# STM32F0x0 register map
File version: 1.2
CPU: CM0 r0p0, little endian, no MPU, no FPU, 3 interrupt priority bits
Registers are 32-bit, read-write, reset 0x0 unless marked. A register's access mark holds for its fields unless they carry their own. Offsets are from the block's base; [hi:lo] are bit positions; {n}, {i} and the like mark numbered series; 'fields as' and 'values as' point back to an identical list.

## IWDG — Independent watchdog
Base 0x40003000
0x00 KR wo — Key register
  [15:0] KEY — Key value
0x04 PR — Prescaler register
  [2:0] PR — Prescaler divider
0x08 RLR reset 0xFFF — Reload register
  [11:0] RL — Watchdog counter reload value
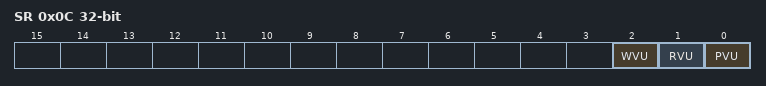
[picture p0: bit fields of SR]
0x0C SR ro — Status register
  [2] WVU — Watchdog counter window value update
  [1] RVU — Watchdog counter reload value update
  [0] PVU — Watchdog prescaler value update
0x10 WINR reset 0xFFF — Window register
  [11:0] WIN — Watchdog counter window value

## WWDG — Window watchdog
Base 0x40002C00
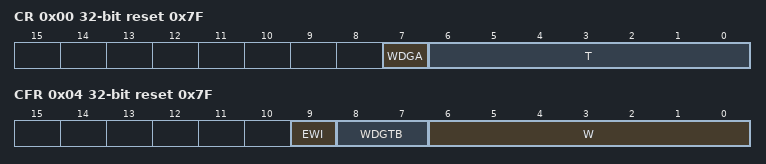
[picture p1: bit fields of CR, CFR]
0x00 CR reset 0x7F — Control register
  [7] WDGA — Activation bit
  [6:0] T — 7-bit counter
0x04 CFR reset 0x7F — Configuration register
  [9] EWI — Early wakeup interrupt
  [8:7] WDGTB — Timer base
  [6:0] W — 7-bit window value
0x08 SR — Status register
  [0] EWIF — Early wakeup interrupt flag

## EXTI — External interrupt/event controller
Base 0x40010400
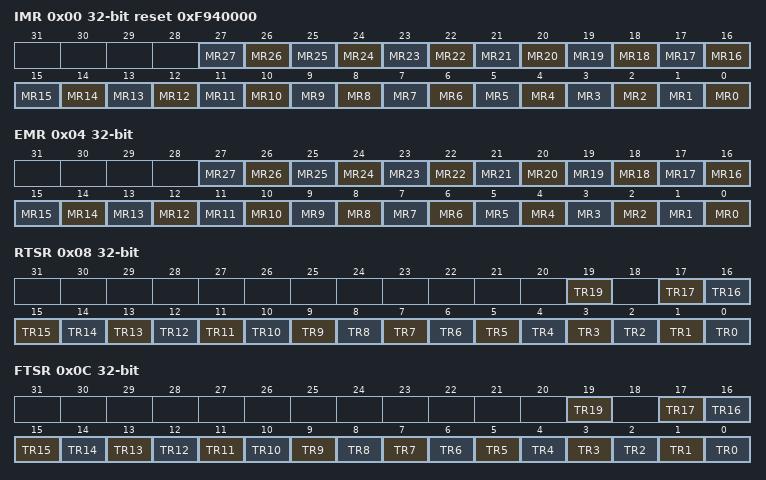
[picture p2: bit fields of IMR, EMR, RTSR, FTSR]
0x00 IMR reset 0xF940000 — Interrupt mask register (EXTI_IMR)
  [n] MR{n} (n=0..27) — Interrupt Mask on line {n}
0x04 EMR — Event mask register (EXTI_EMR)
  [n] MR{n} (n=0..27) — Event Mask on line {n}
0x08 RTSR — Rising Trigger selection register (EXTI_RTSR)
  [19] TR19 — Rising trigger event configuration of line 19
  [n] TR{n} (n=0..17) — Rising trigger event configuration of line {n}
0x0C FTSR — Falling Trigger selection register (EXTI_FTSR)
  [19] TR19 — Falling trigger event configuration of line 19
  [n] TR{n} (n=0..17) — Falling trigger event configuration of line {n}
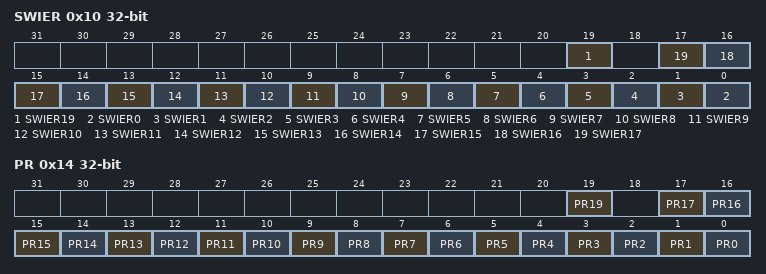
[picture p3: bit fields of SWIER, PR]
0x10 SWIER — Software interrupt event register (EXTI_SWIER)
  [19] SWIER19 — Software Interrupt on line 19
  [n] SWIER{n} (n=0..17) — Software Interrupt on line {n}
0x14 PR — Pending register (EXTI_PR)
  [19] PR19 — Pending bit 19
  [n] PR{n} (n=0..17) — Pending bit {n}

## NVIC — Nested Vectored Interrupt Controller
Base 0xE000E100
0x00 ISER — Interrupt Set Enable Register
  [31:0] SETENA
0x80 ICER — Interrupt Clear Enable Register
  [31:0] CLRENA
0x100 ISPR — Interrupt Set-Pending Register
  [31:0] SETPEND
0x180 ICPR — Interrupt Clear-Pending Register
  [31:0] CLRPEND
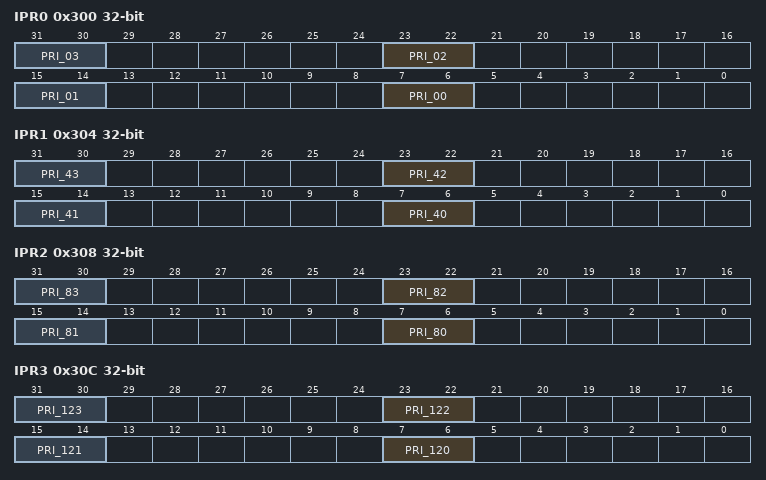
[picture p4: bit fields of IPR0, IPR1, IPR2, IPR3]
0x300 IPR0 — Interrupt Priority Register 0
  [8n+7:8n+6] PRI_{n:02} (n=0..3)
0x304 IPR1 — Interrupt Priority Register 1
  [8n-313:8n-314] PRI_{n} (n=40..43)
0x308 IPR2 — Interrupt Priority Register 2
  [8n-633:8n-634] PRI_{n} (n=80..83)
0x30C IPR3 — Interrupt Priority Register 3
  [8n-953:8n-954] PRI_{n} (n=120..123)
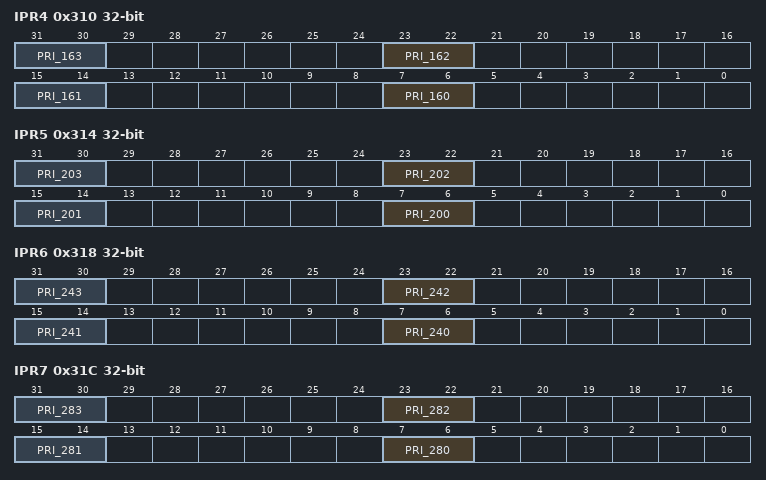
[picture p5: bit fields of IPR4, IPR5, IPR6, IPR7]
0x310 IPR4 — Interrupt Priority Register 4
  [8n-1273:8n-1274] PRI_{n} (n=160..163)
0x314 IPR5 — Interrupt Priority Register 5
  [8n-1593:8n-1594] PRI_{n} (n=200..203)
0x318 IPR6 — Interrupt Priority Register 6
  [8n-1913:8n-1914] PRI_{n} (n=240..243)
0x31C IPR7 — Interrupt Priority Register 7
  [8n-2233:8n-2234] PRI_{n} (n=280..283)

## DMA1 — DMA controller
Base 0x40020000
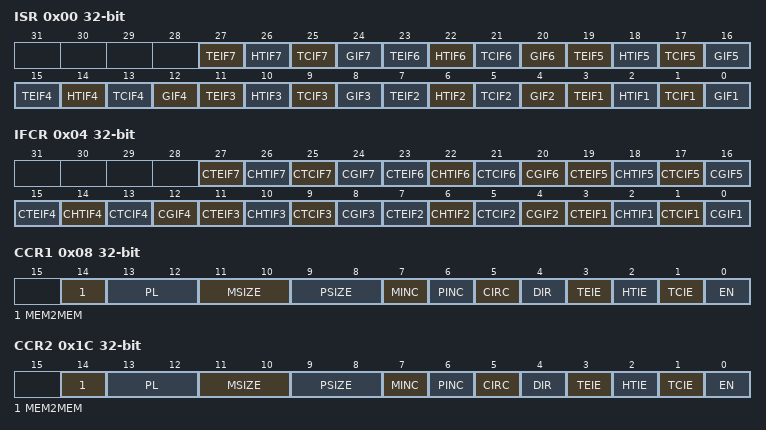
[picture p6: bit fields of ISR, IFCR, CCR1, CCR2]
0x00 ISR ro — DMA interrupt status register (DMA_ISR)
  [4n-1] TEIF{n} (n=1..7) — Channel {n} Transfer Error flag
  [4n-2] HTIF{n} (n=1..7) — Channel {n} Half Transfer Complete flag
  [4n-3] TCIF{n} (n=1..7) — Channel {n} Transfer Complete flag
  [4n-4] GIF{n} (n=1..7) — Channel {n} Global interrupt flag
0x04 IFCR wo — DMA interrupt flag clear register (DMA_IFCR)
  [4n-1] CTEIF{n} (n=1..7) — Channel {n} Transfer Error clear
  [4n-2] CHTIF{n} (n=1..7) — Channel {n} Half Transfer clear
  [4n-3] CTCIF{n} (n=1..7) — Channel {n} Transfer Complete clear
  [4n-4] CGIF{n} (n=1..7) — Channel {n} Global interrupt clear
0x08 CCR1 — DMA channel configuration register (DMA_CCR)
  [14] MEM2MEM — Memory to memory mode
  [13:12] PL — Channel Priority level
  [11:10] MSIZE — Memory size
  [9:8] PSIZE — Peripheral size
  [7] MINC — Memory increment mode
  [6] PINC — Peripheral increment mode
  [5] CIRC — Circular mode
  [4] DIR — Data transfer direction
  [3] TEIE — Transfer error interrupt enable
  [2] HTIE — Half Transfer interrupt enable
  [1] TCIE — Transfer complete interrupt enable
  [0] EN — Channel enable
0x0C CNDTR1 — DMA channel 1 number of data register
  [15:0] NDT — Number of data to transfer
0x10 CPAR1 — DMA channel 1 peripheral address register
  [31:0] PA — Peripheral address
{0x0+0x14*i} CMAR{i} (i=1..7) — DMA channel {i} memory address register
  [31:0] MA — Memory address
0x1C CCR2 — DMA channel configuration register (DMA_CCR)
  fields as CCR1
0x20 CNDTR2 — DMA channel 2 number of data register
  [15:0] NDT — Number of data to transfer
0x24 CPAR2 — DMA channel 2 peripheral address register
  [31:0] PA — Peripheral address
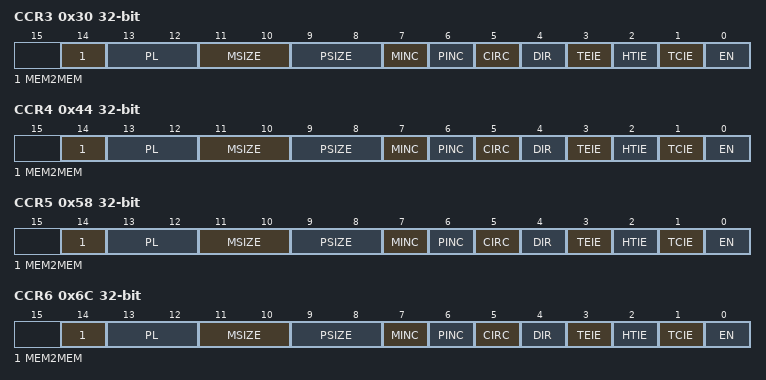
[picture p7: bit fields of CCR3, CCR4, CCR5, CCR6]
0x30 CCR3 — DMA channel configuration register (DMA_CCR)
  fields as CCR1
0x34 CNDTR3 — DMA channel 3 number of data register
  [15:0] NDT — Number of data to transfer
0x38 CPAR3 — DMA channel 3 peripheral address register
  [31:0] PA — Peripheral address
0x44 CCR4 — DMA channel configuration register (DMA_CCR)
  fields as CCR1
0x48 CNDTR4 — DMA channel 4 number of data register
  [15:0] NDT — Number of data to transfer
0x4C CPAR4 — DMA channel 4 peripheral address register
  [31:0] PA — Peripheral address
0x58 CCR5 — DMA channel configuration register (DMA_CCR)
  fields as CCR1
0x5C CNDTR5 — DMA channel 5 number of data register
  [15:0] NDT — Number of data to transfer
0x60 CPAR5 — DMA channel 5 peripheral address register
  [31:0] PA — Peripheral address
0x6C CCR6 — DMA channel configuration register (DMA_CCR)
  fields as CCR1
0x70 CNDTR6 — DMA channel 6 number of data register
  [15:0] NDT — Number of data to transfer
0x74 CPAR6 — DMA channel 6 peripheral address register
  [31:0] PA — Peripheral address
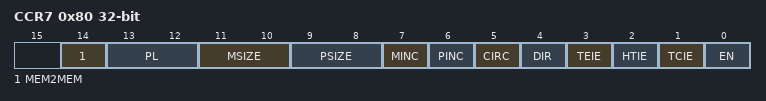
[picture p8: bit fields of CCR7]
0x80 CCR7 — DMA channel configuration register (DMA_CCR)
  fields as CCR1
0x84 CNDTR7 — DMA channel 7 number of data register
  [15:0] NDT — Number of data to transfer
0x88 CPAR7 — DMA channel 7 peripheral address register
  [31:0] PA — Peripheral address
